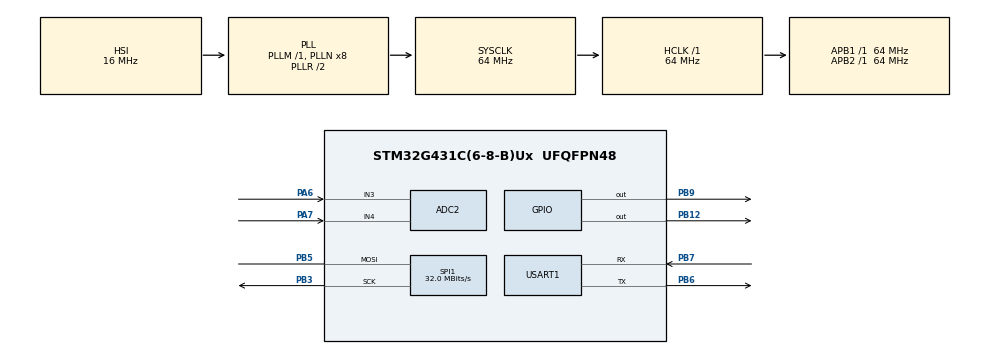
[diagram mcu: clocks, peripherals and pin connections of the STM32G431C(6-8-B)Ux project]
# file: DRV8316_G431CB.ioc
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ADC2.Channel-0\#ChannelRegularConversion=ADC_CHANNEL_3
ADC2.NbrOfConversionFlag=1
ADC2.OffsetNumber-0\#ChannelRegularConversion=ADC_OFFSET_NONE
ADC2.Rank-0\#ChannelRegularConversion=1
ADC2.SamplingTime-0\#ChannelRegularConversion=ADC_SAMPLETIME_2CYCLES_5
ADC2.SingleDiff-0\#ChannelRegularConversion=ADC_DIFFERENTIAL_ENDED
Mcu.Family=STM32G4
Mcu.Name=STM32G431C(6-8-B)Ux
Mcu.Package=UFQFPN48
NVIC.PriorityGroup=NVIC_PRIORITYGROUP_4
PA10.Signal=S_TIM1_CH3
PA13.Mode=Serial_Wire
PA13.Signal=SYS_JTMS-SWDIO
PA14.Mode=Serial_Wire
PA14.Signal=SYS_JTCK-SWCLK
PA5.Signal=ADC2_IN13
PA6.Mode=IN3-Differential
PA6.Signal=ADC2_IN3
PA7.Mode=IN3-Differential
PA7.Signal=ADC2_IN4
PA8.Signal=S_TIM1_CH1
PA9.Signal=S_TIM1_CH2
PB12.GPIO_PuPd=GPIO_PULLDOWN
PB12.Signal=GPIO_Output
PB13.Signal=TIM1_CH1N
PB14.Signal=TIM1_CH2N
PB15.Signal=TIM1_CH3N
PB3.Mode=Simplex_Bidirectional_Master
PB3.Signal=SPI1_SCK
PB4.Signal=SPI1_MISO
PB5.Mode=Simplex_Bidirectional_Master
PB5.Signal=SPI1_MOSI
PB6.Mode=Asynchronous
PB6.Signal=USART1_TX
PB7.Mode=Asynchronous
PB7.Signal=USART1_RX
PB9.GPIO_PuPd=GPIO_PULLDOWN
PB9.GPIO_Speed=GPIO_SPEED_FREQ_MEDIUM
PB9.Signal=GPIO_Output
PF0-OSC_IN.Mode=HSE-External-Oscillator
PF0-OSC_IN.Signal=RCC_OSC_IN
PF1-OSC_OUT.Mode=HSE-External-Oscillator
PF1-OSC_OUT.Signal=RCC_OSC_OUT
ProjectManager.HeapSize=0x200
ProjectManager.StackSize=0x400
ProjectManager.TargetToolchain=STM32CubeIDE
RCC.ADC12Freq_Value=64000000
RCC.AHBFreq_Value=64000000
RCC.APB1Freq_Value=64000000
RCC.APB1TimFreq_Value=64000000
RCC.APB2Freq_Value=64000000
RCC.APB2TimFreq_Value=64000000
RCC.CortexFreq_Value=64000000
RCC.EXTERNAL_CLOCK_VALUE=12288000
RCC.HCLKFreq_Value=64000000
RCC.HSE_VALUE=16000000
RCC.HSI48_VALUE=48000000
RCC.HSI_VALUE=16000000
RCC.LSE_VALUE=32768
RCC.SYSCLKFreq_VALUE=64000000
RCC.SYSCLKSource=RCC_SYSCLKSOURCE_PLLCLK
RCC.USBFreq_Value=64000000
RCC.VCOOutputFreq_Value=128000000
SH.S_TIM1_CH1.0=TIM1_CH1
SH.S_TIM1_CH2.0=TIM1_CH2
SH.S_TIM1_CH3.0=TIM1_CH3
SPI1.CalculateBaudRate=32.0 MBits/s
SPI1.Direction=SPI_DIRECTION_1LINE
SPI1.Mode=SPI_MODE_MASTER
SPI1.VirtualType=VM_MASTER
USART1.VirtualMode-Asynchronous=VM_ASYNC
VP_SYS_VS_DBSignals.Mode=DisableDeadBatterySignals
VREF+.Mode=InternalMode
VREF+.Signal=VREFBUF_OUT
board=custom

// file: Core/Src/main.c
/* USER CODE BEGIN Header */
/**
  ******************************************************************************
  * @file           : main.c
  * @brief          : Main program body
  ******************************************************************************
  * @attention
  *
  * Copyright (c) 2026 STMicroelectronics.
  * All rights reserved.
  *
  * This software is licensed under terms that can be found in the LICENSE file
  * in the root directory of this software component.
  * If no LICENSE file comes with this software, it is provided AS-IS.
  *
  ******************************************************************************
  */
/* USER CODE END Header */
#include "main.h"
#include "adc.h"
#include "spi.h"
#include "usart.h"
#include "gpio.h"
#include "drv8316.h"

void SystemClock_Config(void);

/* USER CODE BEGIN 0 */
DRV8316_Handle drvHandle;
DRV8316_Obj drvObj;

/* USER CODE END 0 */

int main(void)
{

  /* MCU Configuration--------------------------------------------------------*/

  /* Reset of all peripherals, Initializes the Flash interface and the Systick. */
  HAL_Init();

  /* Configure the system clock */
  SystemClock_Config();

  /* Initialize all configured peripherals */
  MX_GPIO_Init();
  MX_ADC2_Init();
  MX_SPI1_Init();
  MX_USART1_UART_Init();
  /* USER CODE BEGIN 2 */
  drvHandle = DRV8316_init(&drvObj);
  DRV8316_setGPIOCSNumber(drvHandle, 47);
  DRV8316_setGPIONumber(drvHandle, 25);
  DRV8316_enable(drvHandle);

  /* USER CODE END 2 */

  /* Infinite loop */
  while (1)
  {

  }
}

void SystemClock_Config(void)
{
  RCC_OscInitTypeDef RCC_OscInitStruct = {0};
  RCC_ClkInitTypeDef RCC_ClkInitStruct = {0};

  /** Configure the main internal regulator output voltage
  */
  HAL_PWREx_ControlVoltageScaling(PWR_REGULATOR_VOLTAGE_SCALE1);

  /** Initializes the RCC Oscillators according to the specified parameters
  * in the RCC_OscInitTypeDef structure.
  */
  RCC_OscInitStruct.OscillatorType = RCC_OSCILLATORTYPE_HSI;
  RCC_OscInitStruct.HSIState = RCC_HSI_ON;
  RCC_OscInitStruct.HSICalibrationValue = RCC_HSICALIBRATION_DEFAULT;
  RCC_OscInitStruct.PLL.PLLState = RCC_PLL_ON;
  RCC_OscInitStruct.PLL.PLLSource = RCC_PLLSOURCE_HSI;
  RCC_OscInitStruct.PLL.PLLM = RCC_PLLM_DIV1;
  RCC_OscInitStruct.PLL.PLLN = 8;
  RCC_OscInitStruct.PLL.PLLP = RCC_PLLP_DIV2;
  RCC_OscInitStruct.PLL.PLLQ = RCC_PLLQ_DIV2;
  RCC_OscInitStruct.PLL.PLLR = RCC_PLLR_DIV2;
  if (HAL_RCC_OscConfig(&RCC_OscInitStruct) != HAL_OK)
  {
    Error_Handler();
  }

  /** Initializes the CPU, AHB and APB buses clocks
  */
  RCC_ClkInitStruct.ClockType = RCC_CLOCKTYPE_HCLK|RCC_CLOCKTYPE_SYSCLK
                              |RCC_CLOCKTYPE_PCLK1|RCC_CLOCKTYPE_PCLK2;
  RCC_ClkInitStruct.SYSCLKSource = RCC_SYSCLKSOURCE_PLLCLK;
  RCC_ClkInitStruct.AHBCLKDivider = RCC_SYSCLK_DIV1;
  RCC_ClkInitStruct.APB1CLKDivider = RCC_HCLK_DIV1;
  RCC_ClkInitStruct.APB2CLKDivider = RCC_HCLK_DIV1;

  if (HAL_RCC_ClockConfig(&RCC_ClkInitStruct, FLASH_LATENCY_2) != HAL_OK)
  {
    Error_Handler();
  }
}

void Error_Handler(void)
{
  __disable_irq();
  while (1)
  {
  }
}
